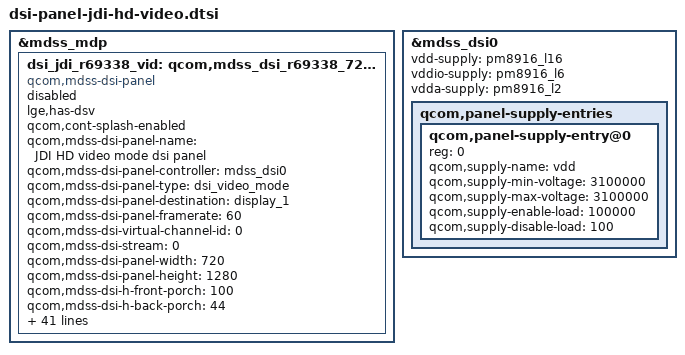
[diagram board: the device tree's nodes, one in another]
&mdss_mdp {
    dsi_jdi_r69338_vid: qcom,mdss_dsi_r69338_720p_video{
            lge,has-dsv;
            compatible = "qcom,mdss-dsi-panel";
            status = "disable";
            qcom,cont-splash-enabled;
            qcom,mdss-dsi-panel-name = "JDI HD video mode dsi panel";
            qcom,mdss-dsi-panel-controller = <&mdss_dsi0>;
            qcom,mdss-dsi-panel-type = "dsi_video_mode";
            qcom,mdss-dsi-panel-destination = "display_1";
            qcom,mdss-dsi-panel-framerate = <60>;
            qcom,mdss-dsi-virtual-channel-id = <0>;
            qcom,mdss-dsi-stream = <0>;
            qcom,mdss-dsi-panel-width = <720>;
            qcom,mdss-dsi-panel-height = <1280>;
            qcom,mdss-dsi-h-front-porch = <100>;
            qcom,mdss-dsi-h-back-porch = <44>;
            qcom,mdss-dsi-h-pulse-width = <4>;
            qcom,mdss-dsi-h-sync-skew = <0>;
            qcom,mdss-dsi-v-back-porch = <3>;
            qcom,mdss-dsi-v-front-porch = <6>;
            qcom,mdss-dsi-v-pulse-width = <1>;
            qcom,mdss-dsi-h-left-border = <0>;
            qcom,mdss-dsi-h-right-border = <0>;
            qcom,mdss-dsi-v-top-border = <0>;
            qcom,mdss-dsi-v-bottom-border = <0>;
            qcom,mdss-pan-physical-width-dimension = <58>;
            qcom,mdss-pan-physical-height-dimension = <104>;
            qcom,mdss-dsi-bpp = <24>;
            qcom,mdss-dsi-color-order = "rgb_swap_rgb";
            qcom,mdss-dsi-underflow-color = <0x0>;
            //qcom,mdss-dsi-lp11-init = <1>;    //need to check
            qcom,mdss-dsi-border-color = <0>;
            qcom,mdss-dsi-on-command = [
				39 01 00 00 00 00 02
				51 ff

				39 01 00 00 00 00 02
				53 0c			//BCTRL Off (2c => 0c)

				39 01 00 00 00 00 02
				55 00			//SRE Off (40 => 00)

				29 01 00 00 00 00 02
				b0 04

				29 01 00 00 00 00 14
				ec 29 00 2c 2b 01 00
				00 00 00 00 00 00 00
				00 00 00 07 09 00

				29 01 00 00 00 00 0f
				ee 1c 02 02 03 00 10
				00 02 00 00 00 00 00
				03

				29 01 00 00 00 00 1F /* gamma setting 1 */
				C7 00 0A 16 20 2C 39
				43 52 36 3E 4B 58 5A
				5F 67 00 0A 16 20 2C
				39 43 52 36 3E 4B 58
				5A 5F 67

				29 01 00 00 00 00 14 /* gamma setting 2 */
				C8 00 00 00 00 00 FC
				00 00 00 00 00 FC 00
				00 00 00 00 FC 00

				29 01 00 00 00 00 1F
				C1 84 61 10 52 4A 59
				94 20 03 1C D9 D8 82
				CF B9 07 17 6B D1 80
				41 82 94 52 4A 09 10
				10 10 10

				29 01 00 00 00 00 02
				d6 01

				15 01 00 00 00 00 02
				36 00

				29 01 00 00 00 00 21 /* Color Enhancement */
				CA 01 70 9A 95 A2 98
				95 8F 3F 3F 80 80 08
				80 08 3F 08 90 0C 0C
				0A 06 04 04 00 C8 10
				10 3F 3F 3F 3F

				05 01 00 00 00 00 01
				29

				05 01 00 00 78 00 01
				11

            ];

            qcom,mdss-dsi-off-command = [
                05 01 00 00 14 00 01
                28
                05 01 00 00 50 00 01
                10
            ];

            qcom,mdss-dsi-on-command-state = "dsi_lp_mode";
            qcom,mdss-dsi-off-command-state = "dsi_hs_mode";
            qcom,mdss-dsi-h-sync-pulse = <0>;
            qcom,mdss-dsi-traffic-mode = "non_burst_sync_event";
            qcom,mdss-dsi-lane-map = "lane_map_0123";
            qcom,mdss-dsi-bllp-eof-power-mode;
            qcom,mdss-dsi-bllp-power-mode;
            qcom,mdss-dsi-lane-0-state;
            qcom,mdss-dsi-lane-1-state;
            qcom,mdss-dsi-lane-2-state;
            qcom,mdss-dsi-lane-3-state;

            qcom,mdss-dsi-panel-timings = [77 1A 10 00 3C 40 14 1C 29 03 04 00];
            qcom,mdss-dsi-t-clk-post = <0x04>;
            qcom,mdss-dsi-t-clk-pre = <0x1B>;
            qcom,mdss-dsi-bl-min-level = <1>;
            qcom,mdss-dsi-bl-max-level = <255>;
            qcom,mdss-dsi-dma-trigger = "trigger_sw";
            qcom,mdss-dsi-mdp-trigger = "none";
            //qcom,mdss-dsi-bl-pmic-control-type = "bl_ctrl_wled";
            qcom,mdss-dsi-reset-sequence = <0 10>, <1 20>, <0 2>, <1 20>;
        };
};
&mdss_dsi0 {
    vdd-supply = <&pm8916_l16>;
    vddio-supply = <&pm8916_l6>;
    vdda-supply = <&pm8916_l2>;
    qcom,panel-supply-entries {
        qcom,panel-supply-entry@0 {
            reg = <0>;
            qcom,supply-name = "vdd";
            qcom,supply-min-voltage = <3100000>;
            qcom,supply-max-voltage = <3100000>;
            qcom,supply-enable-load = <100000>;
            qcom,supply-disable-load = <100>;
        };
    };
};

